# FM33FH0XX register map
File version: 1.0
CPU: SC000 r1p0, little endian, no MPU, no FPU, 3 interrupt priority bits
Registers are 32-bit, read-write, reset 0x0 unless marked. A register's access mark holds for its fields unless they carry their own. Offsets are from the block's base; [hi:lo] are bit positions; {n}, {i} and the like mark numbered series.

## TAU0 — TAU0 module information
Base 0x40013C00
0x00 CR
  [7:0] EN — EN field description
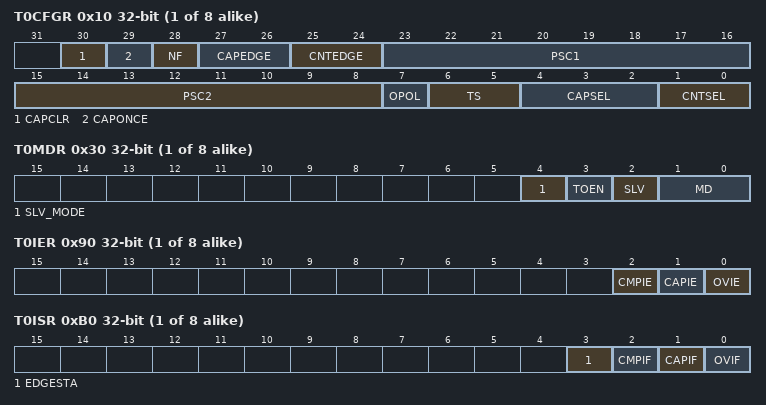
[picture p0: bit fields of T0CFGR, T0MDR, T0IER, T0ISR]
{0x10+4i} T{i}CFGR (i=0..7)
  [30] CAPCLR — CAPCLR field description
  [29] CAPONCE — CAPONCE field description
  [28] NF — NF field description
  [27:26] CAPEDGE — CAPEDGE field description
  [25:24] CNTEDGE — CNTEDGE field description
  [23:16] PSC1 — PSC1 field description
  [15:8] PSC2 — PSC2 field description
  [7] OPOL — OPOL field description
  [6:5] TS — TS field description
  [4:2] CAPSEL — CAPSEL field description
  [1:0] CNTSEL — CNTSEL field description
{0x30+4i} T{i}MDR (i=0..7)
  [4] SLV_MODE — SLV_MODE field description
  [3] TOEN — TOEN field description
  [2] SLV — SLV field description
  [1:0] MD — MD field description
{0x50+4i} T{i}ARR (i=0..7)
  [15:0] ARR — ARR field description
{0x70+4i} T{i}CCR (i=0..7)
  [15:0] CCR — CCR field description
{0x90+4i} T{i}IER (i=0..7)
  [2] CMPIE — CMPIE field description
  [1] CAPIE — CAPIE field description
  [0] OVIE — OVIE field description
{0xB0+4i} T{i}ISR (i=0..7)
  [3] EDGESTA — EDGESTA field description
  [2] CMPIF — CMPIF field description
  [1] CAPIF — CAPIF field description
  [0] OVIF — OVIF field description
{0xD0+4i} T{i}CNT (i=0..7)
  [15:0] CNT ro — CNT field description

## TAU1 — TAU1 module information
Base 0x40013C00
0x04 CR
  [7:0] EN — EN field description
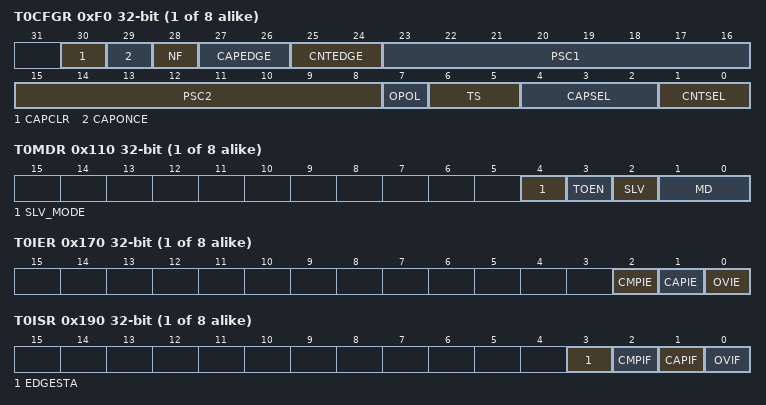
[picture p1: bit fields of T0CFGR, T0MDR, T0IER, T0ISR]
{0xF0+4i} T{i}CFGR (i=0..7)
  [30] CAPCLR — CAPCLR field description
  [29] CAPONCE — CAPONCE field description
  [28] NF — NF field description
  [27:26] CAPEDGE — CAPEDGE field description
  [25:24] CNTEDGE — CNTEDGE field description
  [23:16] PSC1 — PSC1 field description
  [15:8] PSC2 — PSC2 field description
  [7] OPOL — OPOL field description
  [6:5] TS — TS field description
  [4:2] CAPSEL — CAPSEL field description
  [1:0] CNTSEL — CNTSEL field description
{0x110+4i} T{i}MDR (i=0..7)
  [4] SLV_MODE — SLV_MODE field description
  [3] TOEN — TOEN field description
  [2] SLV — SLV field description
  [1:0] MD — MD field description
{0x130+4i} T{i}ARR (i=0..7)
  [15:0] ARR — ARR field description
{0x150+4i} T{i}CCR (i=0..7)
  [15:0] CCR — CCR field description
{0x170+4i} T{i}IER (i=0..7)
  [2] CMPIE — CMPIE field description
  [1] CAPIE — CAPIE field description
  [0] OVIE — OVIE field description
{0x190+4i} T{i}ISR (i=0..7)
  [3] EDGESTA — EDGESTA field description
  [2] CMPIF — CMPIF field description
  [1] CAPIF — CAPIF field description
  [0] OVIF — OVIF field description
{0x1B0+4i} T{i}CNT (i=0..7)
  [15:0] CNT ro — CNT field description

## UART6 — UART6 module information
Base 0x4001B800
Same registers: UART7 0x4001BC00
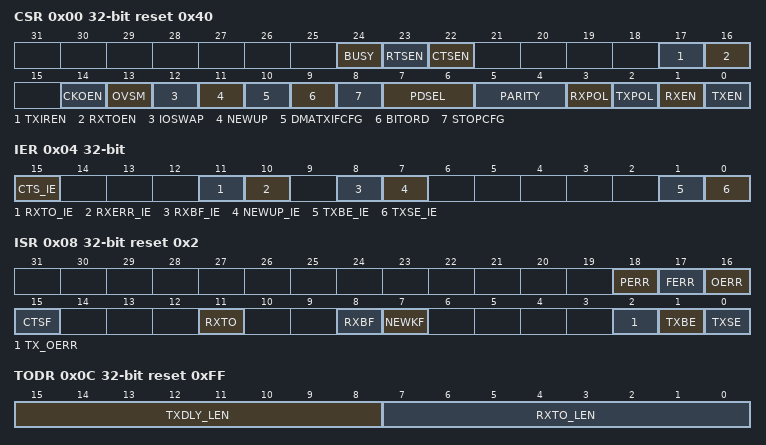
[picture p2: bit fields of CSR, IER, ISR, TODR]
0x00 CSR reset 0x40
  [24] BUSY ro — BUSY field description
  [23] RTSEN — RTSEN field description
  [22] CTSEN — CTSEN field description
  [17] TXIREN — TXIREN field description
  [16] RXTOEN — RXTOEN field description
  [14] CKOEN — CKOEN field description
  [13] OVSM — OVSM field description
  [12] IOSWAP — IOSWAP field description
  [11] NEWUP — NEWUP field description
  [10] DMATXIFCFG — DMATXIFCFG field description
  [9] BITORD — BITORD field description
  [8] STOPCFG — STOPCFG field description
  [7:6] PDSEL — PDSEL field description
  [5:4] PARITY — PARITY field description
  [3] RXPOL — RXPOL field description
  [2] TXPOL — TXPOL field description
  [1] RXEN — RXEN field description
  [0] TXEN — TXEN field description
0x04 IER
  [15] CTS_IE — CTS_IE field description
  [11] RXTO_IE — RXTO_IE field description
  [10] RXERR_IE — RXERR_IE field description
  [8] RXBF_IE — RXBF_IE field description
  [7] NEWUP_IE — NEWUP_IE field description
  [1] TXBE_IE — TXBE_IE field description
  [0] TXSE_IE — TXSE_IE field description
0x08 ISR reset 0x2
  [18] PERR — PERR field description
  [17] FERR — FERR field description
  [16] OERR — OERR field description
  [15] CTSF — CTSF field description
  [11] RXTO — RXTO field description
  [8] RXBF — RXBF field description
  [7] NEWKF — NEWKF field description
  [2] TX_OERR — TX_OERR field description
  [1] TXBE ro — TXBE field description
  [0] TXSE — TXSE field description
0x0C TODR reset 0xFF
  [15:8] TXDLY_LEN — TXDLY_LEN field description
  [7:0] RXTO_LEN — RXTO_LEN field description
0x10 RXBUF
  [8:0] RXBUF ro — RXBUF field description
0x14 TXBUF
  [8:0] TXBUF wo — TXBUF field description
0x18 BRG reset 0x341
  [15:0] SPBRG — SPBRG field description
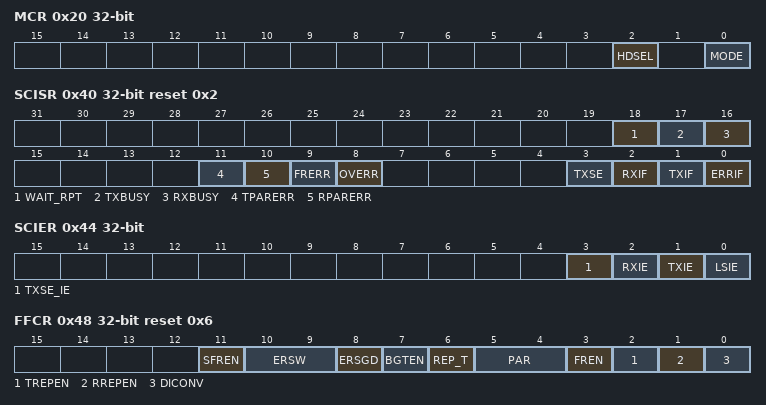
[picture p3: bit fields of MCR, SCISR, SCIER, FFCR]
0x20 MCR
  [2] HDSEL — HDSEL field description
  [0] MODE — MODE field description
0x40 SCISR reset 0x2
  [18] WAIT_RPT ro — WAIT_RPT field description
  [17] TXBUSY ro — TXBUSY field description
  [16] RXBUSY ro — RXBUSY field description
  [11] TPARERR — TPARERR field description
  [10] RPARERR — RPARERR field description
  [9] FRERR — FRERR field description
  [8] OVERR — OVERR field description
  [3] TXSE — TXSE field description
  [2] RXIF ro — RXIF field description
  [1] TXIF ro — TXIF field description
  [0] ERRIF ro — ERRIF field description
0x44 SCIER
  [3] TXSE_IE — TXSE_IE field description
  [2] RXIE — RXIE field description
  [1] TXIE — TXIE field description
  [0] LSIE — LSIE field description
0x48 FFCR reset 0x6
  [11] SFREN — SFREN field description
  [10:9] ERSW — ERSW field description
  [8] ERSGD — ERSGD field description
  [7] BGTEN — BGTEN field description
  [6] REP_T — REP_T field description
  [5:4] PAR — PAR field description
  [3] FREN — FREN field description
  [2] TREPEN — TREPEN field description
  [1] RREPEN — RREPEN field description
  [0] DICONV — DICONV field description
0x4C EGTR
  [7:0] TXEGT — TXEGT field description
0x50 CODR reset 0x3
  [4:0] CLKDIV — CLKDIV field description

## UARTIR — UARTIR module information
Base 0x40017C00
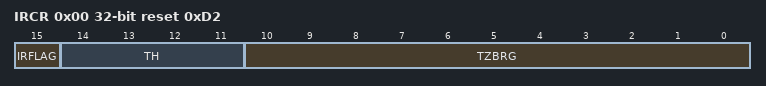
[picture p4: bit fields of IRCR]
0x00 IRCR reset 0xD2
  [15] IRFLAG — IRFLAG field description
  [14:11] TH — TH field description
  [10:0] TZBRG — TZBRG field description

## WWDT — WWDT module information
Base 0x40011800
0x00 CR
  [7:0] CON wo — CON field description
0x04 CFGR reset 0x3
  [2:0] CFG — CFG field description
0x08 CNT
  [9:0] CNT ro — CNT field description
0x0C IER
  [0] IE — IE field description
0x10 ISR
  [0] NOVF — NOVF field description
0x14 PSC
  [11:0] DIV_CNT ro — DIV_CNT field description
